# MB9BF36xx register map
File version: 1.0
CPU: 
Registers are 8-bit, read-write, reset 0x0 unless marked. A register's access mark holds for its fields unless they carry their own. Offsets are from the block's base; [hi:lo] are bit positions; {n}, {i} and the like mark numbered series.

## LCR — peripheral LCR
Base 0x4003C000
0x00 LCR_PRSLD
  [5:0] LCR_PRSLD

## CLK_GATING — peripheral CLK_GATING
Base 0x4003C100
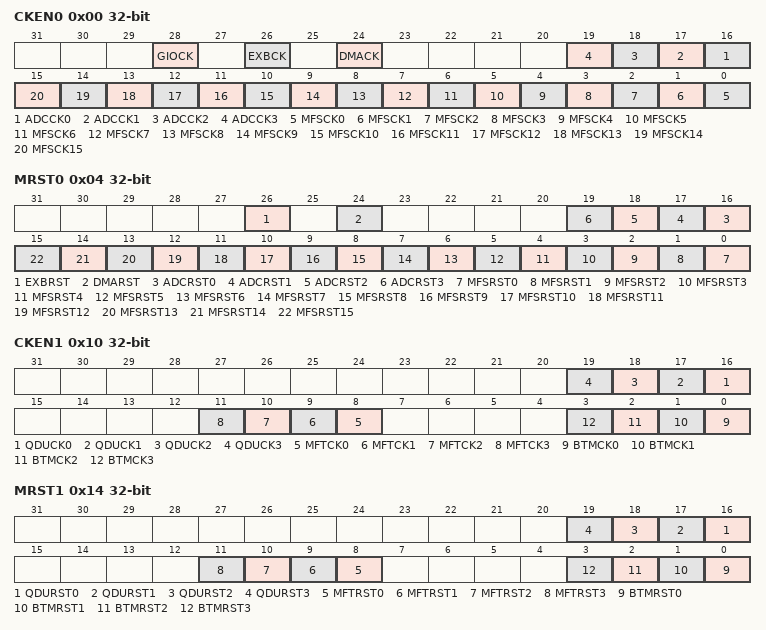
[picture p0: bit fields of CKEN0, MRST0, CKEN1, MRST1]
0x00 CKEN0 32-bit
  [28] GIOCK, [26] EXBCK, [24] DMACK, [n+16] ADCCK{n} (n=0..3), [n] MFSCK{n} (n=0..15)
0x04 MRST0 32-bit reset not defined
  [26] EXBRST, [24] DMARST, [n+16] ADCRST{n} (n=0..3), [n] MFSRST{n} (n=0..15)
0x10 CKEN1 32-bit
  [n+16] QDUCK{n} (n=0..3), [n+8] MFTCK{n} (n=0..3), [n] BTMCK{n} (n=0..3)
0x14 MRST1 32-bit reset not defined
  [n+16] QDURST{n} (n=0..3), [n+8] MFTRST{n} (n=0..3), [n] BTMRST{n} (n=0..3)
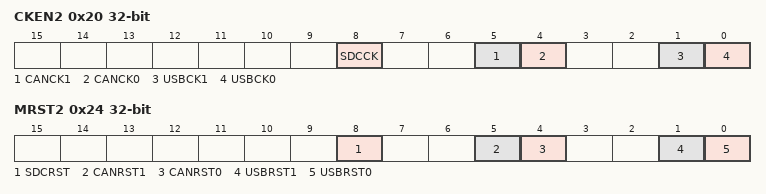
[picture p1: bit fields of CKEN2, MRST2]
0x20 CKEN2 32-bit (reset mask 0x30)
  [8] SDCCK, [5] CANCK1, [4] CANCK0, [1] USBCK1, [0] USBCK0
0x24 MRST2 32-bit reset not defined
  [8] SDCRST, [5] CANRST1, [4] CANRST0, [1] USBRST1, [0] USBRST0

## PLL_CONTROL — peripheral PLL_CONTROL
Base 0x4003C800
0x00 SSCTL1 32-bit (reset mask 0x31)
0x04 SSCTL2 32-bit (reset mask 0x3FF)

## EXBUS — peripheral EXBUS
Base 0x4003F000
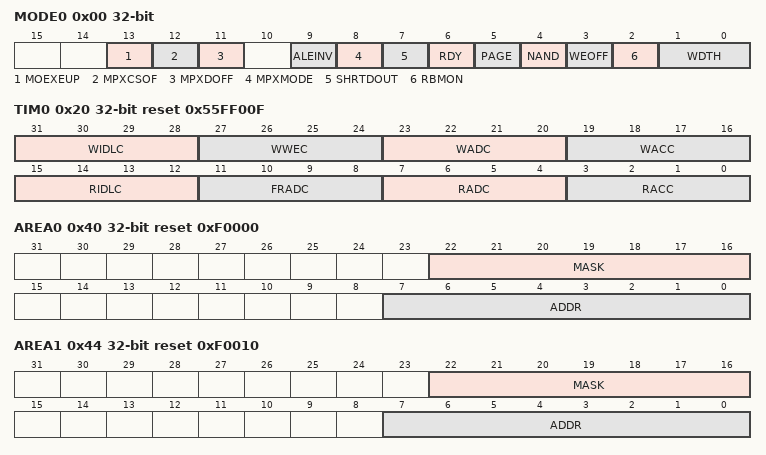
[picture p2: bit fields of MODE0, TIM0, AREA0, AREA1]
0x00 MODE0 32-bit
  [13] MOEXEUP, [12] MPXCSOF, [11] MPXDOFF, [9] ALEINV, [8] MPXMODE, [7] SHRTDOUT, [6] RDY, [5] PAGE, [4] NAND, [3] WEOFF, [2] RBMON, [1:0] WDTH
{0x0+4i} MODE{i} 32-bit reset not defined (i=1..7)
0x20 TIM0 32-bit reset 0x55FF00F
  [31:28] WIDLC, [27:24] WWEC, [23:20] WADC, [19:16] WACC, [15:12] RIDLC, [11:8] FRADC, [7:4] RADC, [3:0] RACC
{0x20+4i} TIM{i} 32-bit reset not defined (i=1..7)
0x40 AREA0 32-bit reset 0xF0000
  [22:16] MASK, [7:0] ADDR
0x44 AREA1 32-bit reset 0xF0010
  [22:16] MASK, [7:0] ADDR
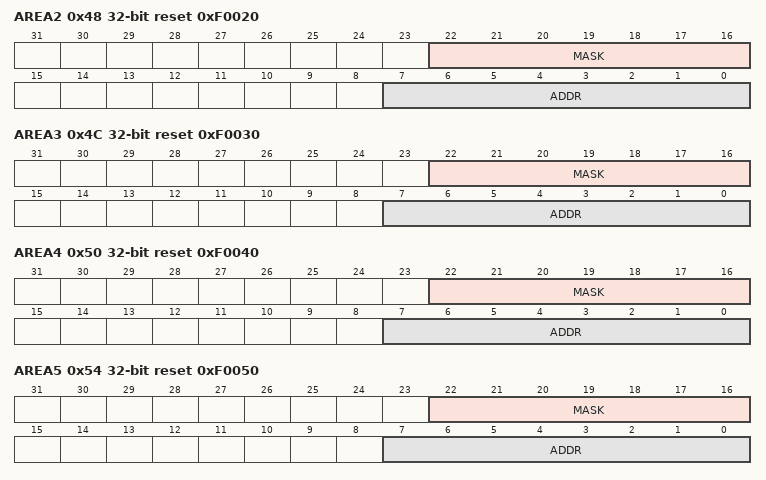
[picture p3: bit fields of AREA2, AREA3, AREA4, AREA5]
0x48 AREA2 32-bit reset 0xF0020
  [22:16] MASK, [7:0] ADDR
0x4C AREA3 32-bit reset 0xF0030
  [22:16] MASK, [7:0] ADDR
0x50 AREA4 32-bit reset 0xF0040
  [22:16] MASK, [7:0] ADDR
0x54 AREA5 32-bit reset 0xF0050
  [22:16] MASK, [7:0] ADDR
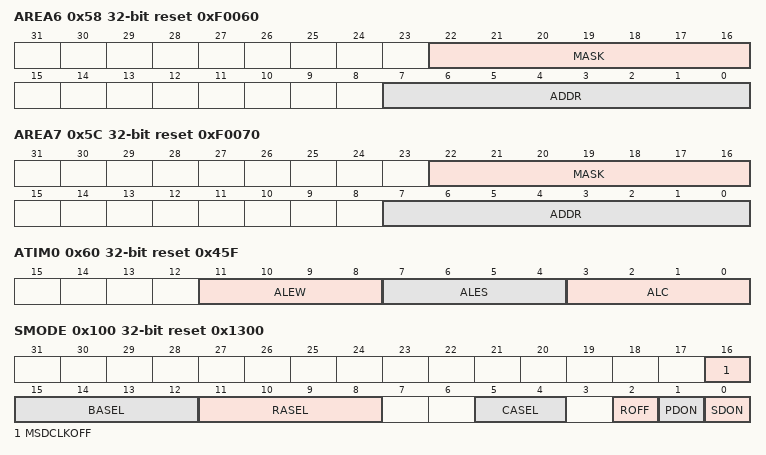
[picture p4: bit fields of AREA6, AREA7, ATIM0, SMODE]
0x58 AREA6 32-bit reset 0xF0060
  [22:16] MASK, [7:0] ADDR
0x5C AREA7 32-bit reset 0xF0070
  [22:16] MASK, [7:0] ADDR
0x60 ATIM0 32-bit reset 0x45F
  [11:8] ALEW, [7:4] ALES, [3:0] ALC
{0x60+4i} ATIM{i} 32-bit reset not defined (i=1..7)
0x100 SMODE 32-bit reset 0x1300
  [16] MSDCLKOFF, [15:12] BASEL, [11:8] RASEL, [5:4] CASEL, [2] ROFF, [1] PDON, [0] SDON
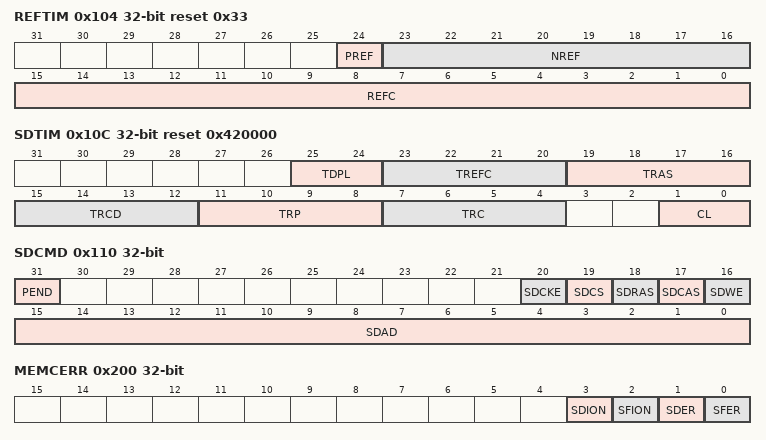
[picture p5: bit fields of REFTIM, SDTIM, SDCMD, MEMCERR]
0x104 REFTIM 32-bit reset 0x33
  [24] PREF, [23:16] NREF, [15:0] REFC
0x108 PWRDWN 32-bit
  [15:0] PDC
0x10C SDTIM 32-bit reset 0x420000
  [25:24] TDPL, [23:20] TREFC, [19:16] TRAS, [15:12] TRCD, [11:8] TRP, [7:4] TRC, [1:0] CL
0x110 SDCMD 32-bit
  [31] PEND ro, [20] SDCKE, [19] SDCS, [18] SDRAS, [17] SDCAS, [16] SDWE, [15:0] SDAD
0x200 MEMCERR 32-bit
  [3] SDION, [2] SFION, [1] SDER, [0] SFER
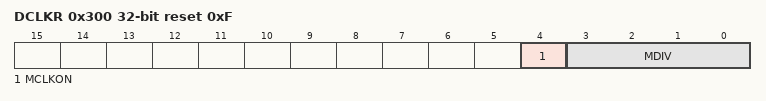
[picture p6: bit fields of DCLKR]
0x300 DCLKR 32-bit reset 0xF
  [4] MCLKON, [3:0] MDIV
0x304 EST 32-bit ro
  [0] WERR
0x308 WEAD 32-bit ro
  [31:0] ADDR
0x30C ESCLR 32-bit wo reset 0x1
  [0] WERRCLR
0x310 AMODE 32-bit reset 0x1
  [0] WAEN

## USBCLK — peripheral USBCLK
Base 0x40036000
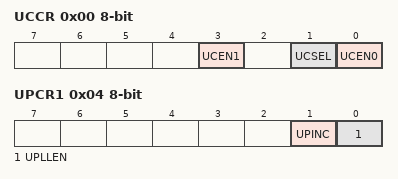
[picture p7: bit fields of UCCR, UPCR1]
0x00 UCCR
  [3] UCEN1, [1] UCSEL, [0] UCEN0
0x04 UPCR1
  [1] UPINC, [0] UPLLEN
0x08 UPCR2
  [2:0] UPOWT
0x0C UPCR3
  [4:0] UPLLK
0x10 UPCR4 reset 0x3B
  [6:0] UPLLN
0x14 UP_STR ro
  [0] UPRDY
0x18 UPINT_ENR
  [0] UPCSE
0x1C UPINT_CLR wo
  [0] UPCSC
0x20 UPINT_STR ro
  [0] UPCSI
0x24 UPCR5 reset 0x4
  [3:0] UPLLM
0x30 USBEN0
  [0] USBEN0
0x34 USBEN1
  [0] USBEN1

## USB0 — peripheral USB0
Base 0x40040000
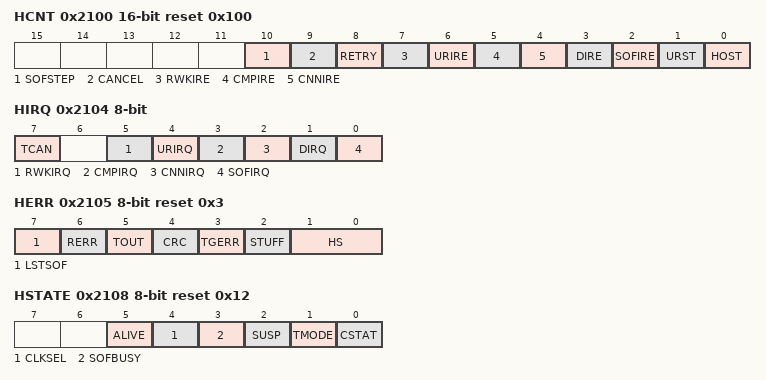
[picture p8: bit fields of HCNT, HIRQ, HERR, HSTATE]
0x2100 HCNT 16-bit reset 0x100
  [10] SOFSTEP, [9] CANCEL, [8] RETRY, [7] RWKIRE, [6] URIRE, [5] CMPIRE, [4] CNNIRE, [3] DIRE, [2] SOFIRE, [1] URST, [0] HOST
0x2104 HIRQ
  [7] TCAN, [5] RWKIRQ, [4] URIRQ, [3] CMPIRQ, [2] CNNIRQ, [1] DIRQ, [0] SOFIRQ
0x2105 HERR reset 0x3
  [7] LSTSOF, [6] RERR, [5] TOUT, [4] CRC, [3] TGERR, [2] STUFF, [1:0] HS
0x2108 HSTATE reset 0x12
  [5] ALIVE, [4] CLKSEL, [3] SOFBUSY, [2] SUSP, [1] TMODE ro, [0] CSTAT ro
0x2109 HFCOMP
  [7:0] FRAMECOMP
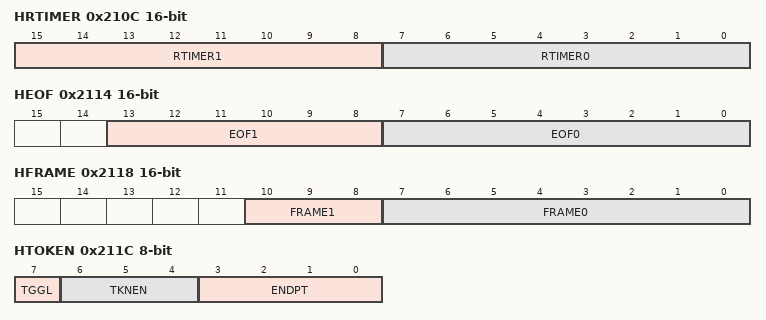
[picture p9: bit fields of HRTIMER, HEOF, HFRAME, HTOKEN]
0x210C HRTIMER 16-bit
  [15:8] RTIMER1, [7:0] RTIMER0
0x2110 HRTIMER2
  [1:0] RTIMER2
0x2111 HADR
  [6:0] ADDRESS
0x2114 HEOF 16-bit
  [13:8] EOF1, [7:0] EOF0
0x2118 HFRAME 16-bit
  [10:8] FRAME1, [7:0] FRAME0
0x211C HTOKEN
  [7] TGGL, [6:4] TKNEN, [3:0] ENDPT
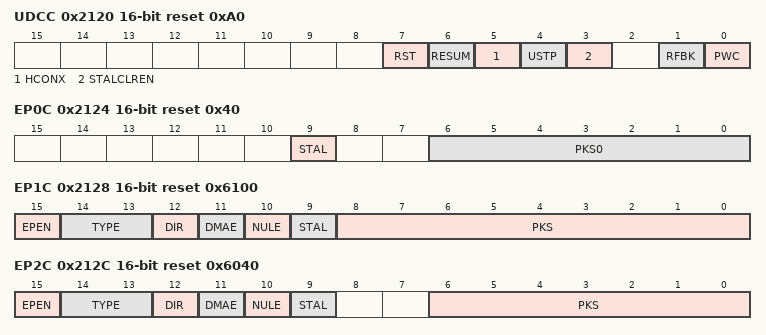
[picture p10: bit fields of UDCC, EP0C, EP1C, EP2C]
0x2120 UDCC 16-bit reset 0xA0
  [7] RST, [6] RESUM, [5] HCONX, [4] USTP, [3] STALCLREN, [1] RFBK, [0] PWC
0x2124 EP0C 16-bit reset 0x40
  [9] STAL, [6:0] PKS0
0x2128 EP1C 16-bit reset 0x6100
  [15] EPEN, [14:13] TYPE, [12] DIR, [11] DMAE, [10] NULE, [9] STAL, [8:0] PKS
0x212C EP2C 16-bit reset 0x6040
  [15] EPEN, [14:13] TYPE, [12] DIR, [11] DMAE, [10] NULE, [9] STAL, [6:0] PKS
{0x2124+4i} EP{i}C 32-bit reset not defined (i=3..5)
0x213C TMSP 16-bit ro
  [10:0] TMSP
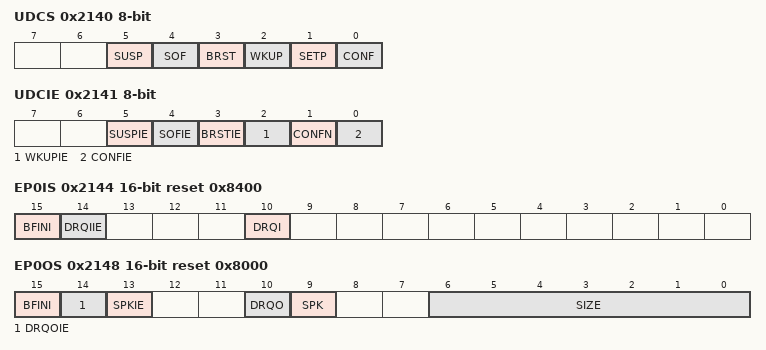
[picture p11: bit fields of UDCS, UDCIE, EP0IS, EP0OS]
0x2140 UDCS
  [5] SUSP, [4] SOF, [3] BRST, [2] WKUP, [1] SETP, [0] CONF
0x2141 UDCIE
  [5] SUSPIE, [4] SOFIE, [3] BRSTIE, [2] WKUPIE, [1] CONFN ro, [0] CONFIE
0x2144 EP0IS 16-bit reset 0x8400
  [15] BFINI, [14] DRQIIE, [10] DRQI
0x2148 EP0OS 16-bit reset 0x8000
  [15] BFINI, [14] DRQOIE, [13] SPKIE, [10] DRQO, [9] SPK, [6:0] SIZE ro
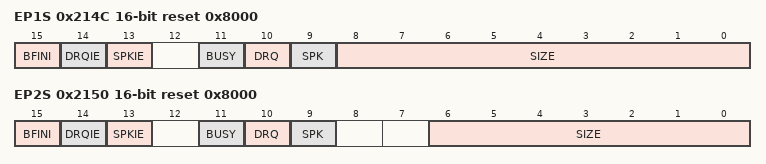
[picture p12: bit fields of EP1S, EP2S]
0x214C EP1S 16-bit reset 0x8000
  [15] BFINI, [14] DRQIE, [13] SPKIE, [11] BUSY ro, [10] DRQ, [9] SPK, [8:0] SIZE ro
0x2150 EP2S 16-bit reset 0x8000
  [15] BFINI, [14] DRQIE, [13] SPKIE, [11] BUSY ro, [10] DRQ, [9] SPK, [6:0] SIZE ro
{0x2148+4i} EP{i}S 32-bit reset not defined (i=3..5)
0x2160 EP0DT 16-bit reset not defined
  [15:0] BFDT
{0x2160+4i} EP{i}DT 32-bit reset not defined (i=1..5)

## DMAC — peripheral DMAC
Base 0x40060000
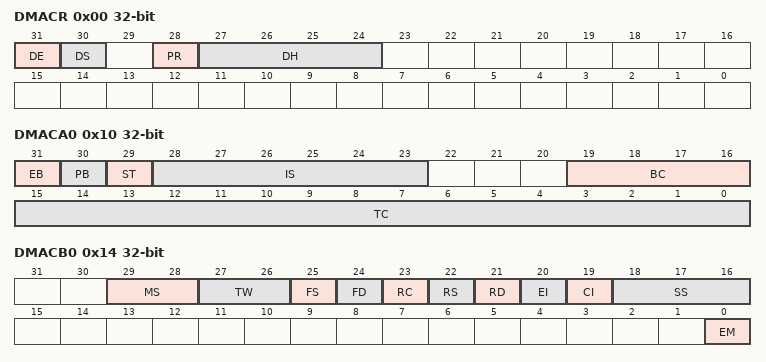
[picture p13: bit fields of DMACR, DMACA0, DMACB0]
0x00 DMACR 32-bit
  [31] DE, [30] DS, [28] PR, [27:24] DH
0x10 DMACA0 32-bit
  [31] EB, [30] PB, [29] ST, [28:23] IS, [19:16] BC, [15:0] TC
0x14 DMACB0 32-bit
  [29:28] MS, [27:26] TW, [25] FS, [24] FD, [23] RC, [22] RS, [21] RD, [20] EI, [19] CI, [18:16] SS, [0] EM
0x18 DMACSA0 32-bit
0x1C DMACDA0 32-bit
{0x10+0x10*i} DMACA{i} 32-bit reset not defined (i=1..7)
{0x14+0x10*i} DMACB{i} 32-bit reset not defined (i=1..7)
{0x18+0x10*i} DMACSA{i} 32-bit reset not defined (i=1..7)
{0x1C+0x10*i} DMACDA{i} 32-bit reset not defined (i=1..7)

## DSTC — peripheral DSTC
Base 0x40061000
0x00 DESTP 32-bit
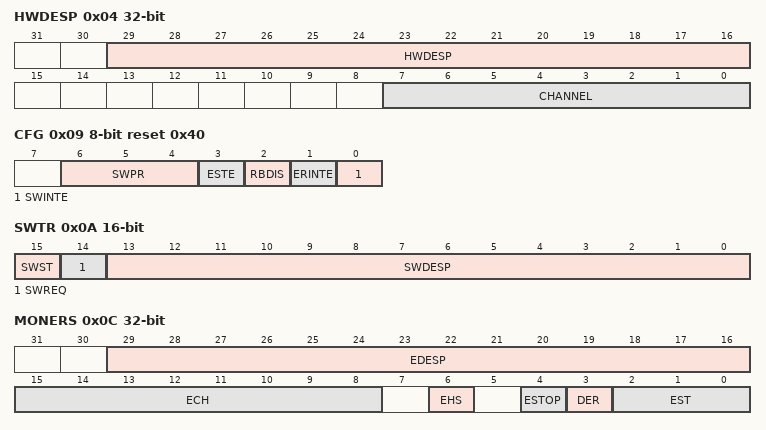
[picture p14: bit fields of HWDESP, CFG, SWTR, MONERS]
0x04 HWDESP 32-bit
  [29:16] HWDESP, [7:0] CHANNEL
0x08 CMD reset 0x1
0x09 CFG reset 0x40
  [6:4] SWPR, [3] ESTE, [2] RBDIS, [1] ERINTE, [0] SWINTE
0x0A SWTR 16-bit
  [15] SWST ro, [14] SWREQ ro, [13:0] SWDESP
0x0C MONERS 32-bit
  [29:16] EDESP ro, [15:8] ECH ro, [6] EHS ro, [4] ESTOP ro, [3] DER ro, [2:0] EST ro
0x10 DREQENB0 32-bit
{0x10+4i} DREQENB{i} 32-bit reset not defined (i=1..7)
0x30 HWINT0 32-bit
{0x30+4i} HWINT{i} 32-bit reset not defined (i=1..7)
0x70 DQMSK0 32-bit
{0x70+4i} DQMSK{i} 32-bit reset not defined (i=1..7)
0x90 DQMSKCLR0 32-bit
{0x90+4i} DQMSKCLR{i} 32-bit reset not defined (i=1..7)

## SDIF — peripheral SDIF
Base 0x4006E000
0x00 DUMMY 32-bit reset not defined
